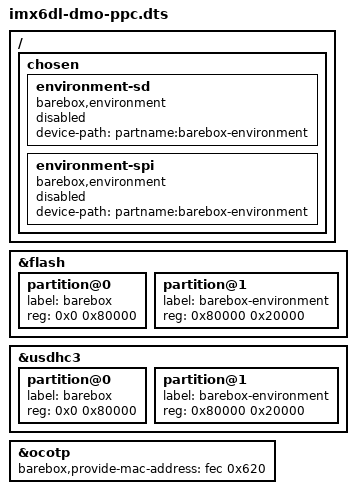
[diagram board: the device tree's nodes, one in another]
/*
 * Copyright 2013-2014 Data-Modul AG
 *
 * The code contained herein is licensed under the GNU General Public
 * License. You may obtain a copy of the GNU General Public License
 * Version 2 or later at the following locations:
 *
 * http://www.opensource.org/licenses/gpl-license.html
 * http://www.gnu.org/copyleft/gpl.html
 */

#include <arm/imx6dl-dmo-ppc.dts>

/ {
	chosen {
		environment-sd {
			compatible = "barebox,environment";
			device-path = &usdhc3, "partname:barebox-environment";
			status = "disabled";
		};

		environment-spi {
			compatible = "barebox,environment";
			device-path = &flash, "partname:barebox-environment";
			status = "disabled";
		};
	};
};

&flash {
	#address-cells = <1>;
	#size-cells = <1>;

	partition@0 {
		label = "barebox";
		reg = <0x0 0x80000>;
	};

	partition@1 {
		label = "barebox-environment";
		reg = <0x80000 0x20000>;
	};
};

&usdhc3 {
	#address-cells = <1>;
	#size-cells = <1>;

	partition@0 {
		label = "barebox";
		reg = <0x0 0x80000>;
	};

	partition@1 {
		label = "barebox-environment";
		reg = <0x80000 0x20000>;
	};
};

&ocotp {
	barebox,provide-mac-address = <&fec 0x620>;
};
